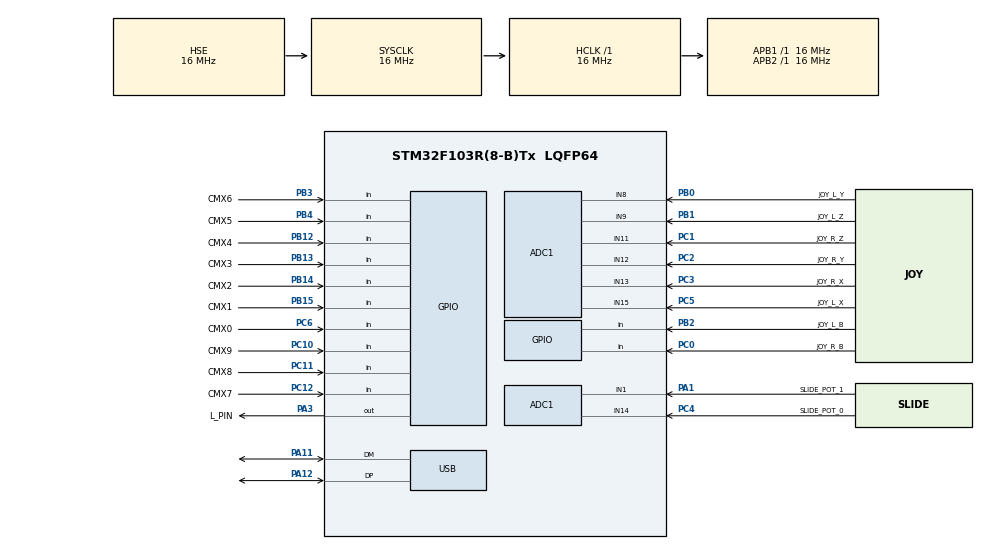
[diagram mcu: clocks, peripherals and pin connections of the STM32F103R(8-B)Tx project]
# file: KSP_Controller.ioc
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ADC1.Channel-0\#ChannelRegularConversion=ADC_CHANNEL_14
ADC1.Channel-1\#ChannelRegularConversion=ADC_CHANNEL_15
ADC1.Channel-2\#ChannelRegularConversion=ADC_CHANNEL_8
ADC1.Channel-3\#ChannelRegularConversion=ADC_CHANNEL_9
ADC1.Channel-4\#ChannelRegularConversion=ADC_CHANNEL_1
ADC1.Channel-5\#ChannelRegularConversion=ADC_CHANNEL_13
ADC1.Channel-6\#ChannelRegularConversion=ADC_CHANNEL_12
ADC1.Channel-7\#ChannelRegularConversion=ADC_CHANNEL_11
ADC1.ContinuousConvMode=DISABLE
ADC1.DiscontinuousConvMode=DISABLE
ADC1.NbrOfConversion=8
ADC1.NbrOfConversionFlag=1
ADC1.Rank-0\#ChannelRegularConversion=1
ADC1.Rank-1\#ChannelRegularConversion=2
ADC1.Rank-2\#ChannelRegularConversion=3
ADC1.Rank-3\#ChannelRegularConversion=4
ADC1.Rank-4\#ChannelRegularConversion=5
ADC1.Rank-5\#ChannelRegularConversion=6
ADC1.Rank-6\#ChannelRegularConversion=7
ADC1.Rank-7\#ChannelRegularConversion=8
ADC1.SamplingTime-0\#ChannelRegularConversion=ADC_SAMPLETIME_1CYCLE_5
ADC1.SamplingTime-1\#ChannelRegularConversion=ADC_SAMPLETIME_1CYCLE_5
ADC1.SamplingTime-2\#ChannelRegularConversion=ADC_SAMPLETIME_1CYCLE_5
ADC1.SamplingTime-3\#ChannelRegularConversion=ADC_SAMPLETIME_1CYCLE_5
ADC1.SamplingTime-4\#ChannelRegularConversion=ADC_SAMPLETIME_1CYCLE_5
ADC1.SamplingTime-5\#ChannelRegularConversion=ADC_SAMPLETIME_1CYCLE_5
ADC1.SamplingTime-6\#ChannelRegularConversion=ADC_SAMPLETIME_1CYCLE_5
ADC1.SamplingTime-7\#ChannelRegularConversion=ADC_SAMPLETIME_1CYCLE_5
ADC1.master=1
Dma.ADC1.0.Direction=DMA_PERIPH_TO_MEMORY
Dma.ADC1.0.Instance=DMA1_Channel1
Dma.ADC1.0.MemDataAlignment=DMA_MDATAALIGN_WORD
Dma.ADC1.0.MemInc=DMA_MINC_ENABLE
Dma.ADC1.0.Mode=DMA_CIRCULAR
Dma.ADC1.0.PeriphDataAlignment=DMA_PDATAALIGN_WORD
Dma.ADC1.0.PeriphInc=DMA_PINC_DISABLE
Dma.ADC1.0.Priority=DMA_PRIORITY_LOW
Dma.Request0=ADC1
Mcu.Family=STM32F1
Mcu.Name=STM32F103R(8-B)Tx
Mcu.Package=LQFP64
NVIC.DMA1_Channel1_IRQn=true\:0\:0\:false\:false\:true\:false\:true\:true
NVIC.PriorityGroup=NVIC_PRIORITYGROUP_4
NVIC.USB_LP_CAN1_RX0_IRQn=true\:0\:0\:false\:false\:true\:false\:true\:true
PA1.GPIO_Label=SLIDE_POT_1
PA1.Signal=ADCx_IN1
PA11.Mode=Device
PA11.Signal=USB_DM
PA12.Mode=Device
PA12.Signal=USB_DP
PA13.Mode=Serial_Wire
PA13.Signal=SYS_JTMS-SWDIO
PA14.Mode=Serial_Wire
PA14.Signal=SYS_JTCK-SWCLK
PA3.GPIO_Label=L_PIN
PA3.GPIO_PuPd=GPIO_PULLDOWN
PA3.Signal=GPIO_Output
PB0.GPIO_Label=JOY_L_Y
PB0.Signal=ADCx_IN8
PB1.GPIO_Label=JOY_L_Z
PB1.Signal=ADCx_IN9
PB12.GPIO_Label=CMX4
PB12.GPIO_PuPd=GPIO_PULLDOWN
PB12.Signal=GPIO_Input
PB13.GPIO_Label=CMX3
PB13.GPIO_PuPd=GPIO_PULLDOWN
PB13.Signal=GPIO_Input
PB14.GPIO_Label=CMX2
PB14.GPIO_PuPd=GPIO_PULLDOWN
PB14.Signal=GPIO_Input
PB15.GPIO_Label=CMX1
PB15.GPIO_PuPd=GPIO_PULLDOWN
PB15.Signal=GPIO_Input
PB2.GPIO_Label=JOY_L_B
PB2.GPIO_PuPd=GPIO_PULLDOWN
PB2.Signal=GPIO_Input
PB3.GPIO_Label=CMX6
PB3.GPIO_PuPd=GPIO_PULLDOWN
PB3.Signal=GPIO_Input
PB4.GPIO_Label=CMX5
PB4.GPIO_PuPd=GPIO_PULLDOWN
PB4.Signal=GPIO_Input
PC0.GPIO_Label=JOY_R_B
PC0.GPIO_PuPd=GPIO_PULLDOWN
PC0.Signal=GPIO_Input
PC1.GPIO_Label=JOY_R_Z
PC1.Signal=ADCx_IN11
PC10.GPIO_Label=CMX9
PC10.GPIO_PuPd=GPIO_PULLDOWN
PC10.Signal=GPIO_Input
PC11.GPIO_Label=CMX8
PC11.GPIO_PuPd=GPIO_PULLDOWN
PC11.Signal=GPIO_Input
PC12.GPIO_Label=CMX7
PC12.GPIO_PuPd=GPIO_PULLDOWN
PC12.Signal=GPIO_Input
PC2.GPIO_Label=JOY_R_Y
PC2.Signal=ADCx_IN12
PC3.GPIO_Label=JOY_R_X
PC3.Signal=ADCx_IN13
PC4.GPIO_Label=SLIDE_POT_0
PC4.Signal=ADCx_IN14
PC5.GPIO_Label=JOY_L_X
PC5.Signal=ADCx_IN15
PC6.GPIO_Label=CMX0
PC6.GPIO_PuPd=GPIO_PULLDOWN
PC6.Signal=GPIO_Input
PD0-OSC_IN.Mode=HSE-External-Oscillator
PD0-OSC_IN.Signal=RCC_OSC_IN
PD1-OSC_OUT.Mode=HSE-External-Oscillator
PD1-OSC_OUT.Signal=RCC_OSC_OUT
ProjectManager.HeapSize=0x1000
ProjectManager.StackSize=0x400
ProjectManager.TargetToolchain=STM32CubeIDE
RCC.AHBFreq_Value=16000000
RCC.APB1Freq_Value=16000000
RCC.APB1TimFreq_Value=16000000
RCC.APB2Freq_Value=16000000
RCC.APB2TimFreq_Value=16000000
RCC.HCLKFreq_Value=16000000
RCC.HSE_VALUE=16000000
RCC.PLLMUL=RCC_PLL_MUL3
RCC.SYSCLKFreq_VALUE=16000000
RCC.SYSCLKSource=RCC_SYSCLKSOURCE_HSE
RCC.USBFreq_Value=48000000
SH.ADCx_IN1.0=ADC1_IN1,IN1
SH.ADCx_IN11.0=ADC1_IN11,IN11
SH.ADCx_IN12.0=ADC1_IN12,IN12
SH.ADCx_IN13.0=ADC1_IN13,IN13
SH.ADCx_IN14.0=ADC1_IN14,IN14
SH.ADCx_IN15.0=ADC1_IN15,IN15
SH.ADCx_IN8.0=ADC1_IN8,IN8
SH.ADCx_IN9.0=ADC1_IN9,IN9
USB_DEVICE.CLASS_NAME_FS=CUSTOM_HID
USB_DEVICE.CUSTOM_HID_FS_BINTERVAL=1
USB_DEVICE.MANUFACTURER_STRING=JLS Hobbies
USB_DEVICE.PID_CUSTOMHID_FS=0x6789
USB_DEVICE.PRODUCT_STRING_CUSTOMHID_FS=KSP Controller
USB_DEVICE.USBD_CUSTOMHID_OUTREPORT_BUF_SIZE=8
USB_DEVICE.USBD_CUSTOM_HID_REPORT_DESC_SIZE=56
USB_DEVICE.USBD_DEBUG_LEVEL=3
USB_DEVICE.USBD_MAX_NUM_CONFIGURATION=1
USB_DEVICE.USBD_MAX_NUM_INTERFACES=1
USB_DEVICE.VID=0x5432
USB_DEVICE.VirtualMode=CustomHid
USB_DEVICE.VirtualModeFS=Custom_Hid_FS
VP_USB_DEVICE_VS_USB_DEVICE_CUSTOM_HID_FS.Mode=CUSTOM_HID_FS
board=custom

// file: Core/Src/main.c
/* USER CODE BEGIN Header */
/**
  ******************************************************************************
  * @file           : main.c
  * @brief          : Main program body
  ******************************************************************************
  * @attention
  *
  * Copyright (c) 2023 STMicroelectronics.
  * All rights reserved.
  *
  * This software is licensed under terms that can be found in the LICENSE file
  * in the root directory of this software component.
  * If no LICENSE file comes with this software, it is provided AS-IS.
  *
  ******************************************************************************
  */
/* USER CODE END Header */
#include "main.h"
#include "usb_device.h"

/* USER CODE BEGIN Includes */
#include "kspcontroller.h"
#include "usbd_customhid.h"
/* USER CODE END Includes */

ADC_HandleTypeDef hadc1;
DMA_HandleTypeDef hdma_adc1;

/* USER CODE BEGIN PV */
extern USBD_HandleTypeDef hUsbDeviceFS;
extern kspControllerHIDStruct kspController;
/* USER CODE END PV */

void SystemClock_Config(void);
static void MX_GPIO_Init(void);
static void MX_DMA_Init(void);
static void MX_ADC1_Init(void);

int main(void)
{

  /* MCU Configuration--------------------------------------------------------*/

  /* Reset of all peripherals, Initializes the Flash interface and the Systick. */
  HAL_Init();

  /* Configure the system clock */
  SystemClock_Config();

  /* Initialize all configured peripherals */
  MX_GPIO_Init();
  MX_DMA_Init();
  MX_USB_DEVICE_Init();
  MX_ADC1_Init();
  /* USER CODE BEGIN 2 */
  kspcontroller_init();
  kspcontroller_setToCentre();

  /* USER CODE END 2 */

  /* Infinite loop */
  while (1)
  {

    /* USER CODE BEGIN 3 */
	  kspcontroller_update();
//	  HAL_Delay(50);
	  USBD_CUSTOM_HID_SendReport(&hUsbDeviceFS, (uint8_t*)&kspController, sizeof(kspController));
//	  HAL_Delay(450);
  }
  /* USER CODE END 3 */
}

void SystemClock_Config(void)
{
  RCC_OscInitTypeDef RCC_OscInitStruct = {0};
  RCC_ClkInitTypeDef RCC_ClkInitStruct = {0};
  RCC_PeriphCLKInitTypeDef PeriphClkInit = {0};

  /** Initializes the RCC Oscillators according to the specified parameters
  * in the RCC_OscInitTypeDef structure.
  */
  RCC_OscInitStruct.OscillatorType = RCC_OSCILLATORTYPE_HSE;
  RCC_OscInitStruct.HSEState = RCC_HSE_ON;
  RCC_OscInitStruct.HSEPredivValue = RCC_HSE_PREDIV_DIV1;
  RCC_OscInitStruct.HSIState = RCC_HSI_ON;
  RCC_OscInitStruct.PLL.PLLState = RCC_PLL_ON;
  RCC_OscInitStruct.PLL.PLLSource = RCC_PLLSOURCE_HSE;
  RCC_OscInitStruct.PLL.PLLMUL = RCC_PLL_MUL3;
  if (HAL_RCC_OscConfig(&RCC_OscInitStruct) != HAL_OK)
  {
    Error_Handler();
  }

  /** Initializes the CPU, AHB and APB buses clocks
  */
  RCC_ClkInitStruct.ClockType = RCC_CLOCKTYPE_HCLK|RCC_CLOCKTYPE_SYSCLK
                              |RCC_CLOCKTYPE_PCLK1|RCC_CLOCKTYPE_PCLK2;
  RCC_ClkInitStruct.SYSCLKSource = RCC_SYSCLKSOURCE_HSE;
  RCC_ClkInitStruct.AHBCLKDivider = RCC_SYSCLK_DIV1;
  RCC_ClkInitStruct.APB1CLKDivider = RCC_HCLK_DIV1;
  RCC_ClkInitStruct.APB2CLKDivider = RCC_HCLK_DIV1;

  if (HAL_RCC_ClockConfig(&RCC_ClkInitStruct, FLASH_LATENCY_0) != HAL_OK)
  {
    Error_Handler();
  }
  PeriphClkInit.PeriphClockSelection = RCC_PERIPHCLK_ADC|RCC_PERIPHCLK_USB;
  PeriphClkInit.AdcClockSelection = RCC_ADCPCLK2_DIV2;
  PeriphClkInit.UsbClockSelection = RCC_USBCLKSOURCE_PLL;
  if (HAL_RCCEx_PeriphCLKConfig(&PeriphClkInit) != HAL_OK)
  {
    Error_Handler();
  }
}

static void MX_ADC1_Init(void)
{

  ADC_ChannelConfTypeDef sConfig = {0};

  /** Common config
  */
  hadc1.Instance = ADC1;
  hadc1.Init.ScanConvMode = ADC_SCAN_ENABLE;
  hadc1.Init.ContinuousConvMode = DISABLE;
  hadc1.Init.DiscontinuousConvMode = DISABLE;
  hadc1.Init.ExternalTrigConv = ADC_SOFTWARE_START;
  hadc1.Init.DataAlign = ADC_DATAALIGN_RIGHT;
  hadc1.Init.NbrOfConversion = 8;
  if (HAL_ADC_Init(&hadc1) != HAL_OK)
  {
    Error_Handler();
  }

  /** Configure Regular Channel
  */
  sConfig.Channel = ADC_CHANNEL_14;
  sConfig.Rank = ADC_REGULAR_RANK_1;
  sConfig.SamplingTime = ADC_SAMPLETIME_1CYCLE_5;
  if (HAL_ADC_ConfigChannel(&hadc1, &sConfig) != HAL_OK)
  {
    Error_Handler();
  }

  /** Configure Regular Channel
  */
  sConfig.Channel = ADC_CHANNEL_15;
  sConfig.Rank = ADC_REGULAR_RANK_2;
  if (HAL_ADC_ConfigChannel(&hadc1, &sConfig) != HAL_OK)
  {
    Error_Handler();
  }

  /** Configure Regular Channel
  */
  sConfig.Channel = ADC_CHANNEL_8;
  sConfig.Rank = ADC_REGULAR_RANK_3;
  if (HAL_ADC_ConfigChannel(&hadc1, &sConfig) != HAL_OK)
  {
    Error_Handler();
  }

  /** Configure Regular Channel
  */
  sConfig.Channel = ADC_CHANNEL_9;
  sConfig.Rank = ADC_REGULAR_RANK_4;
  if (HAL_ADC_ConfigChannel(&hadc1, &sConfig) != HAL_OK)
  {
    Error_Handler();
  }

  /** Configure Regular Channel
  */
  sConfig.Channel = ADC_CHANNEL_1;
  sConfig.Rank = ADC_REGULAR_RANK_5;
  if (HAL_ADC_ConfigChannel(&hadc1, &sConfig) != HAL_OK)
  {
    Error_Handler();
  }

  /** Configure Regular Channel
  */
  sConfig.Channel = ADC_CHANNEL_13;
  sConfig.Rank = ADC_REGULAR_RANK_6;
  if (HAL_ADC_ConfigChannel(&hadc1, &sConfig) != HAL_OK)
  {
    Error_Handler();
  }

  /** Configure Regular Channel
  */
  sConfig.Channel = ADC_CHANNEL_12;
  sConfig.Rank = ADC_REGULAR_RANK_7;
  if (HAL_ADC_ConfigChannel(&hadc1, &sConfig) != HAL_OK)
  {
    Error_Handler();
  }

  /** Configure Regular Channel
  */
  sConfig.Channel = ADC_CHANNEL_11;
  sConfig.Rank = ADC_REGULAR_RANK_8;
  if (HAL_ADC_ConfigChannel(&hadc1, &sConfig) != HAL_OK)
  {
    Error_Handler();
  }

}

static void MX_DMA_Init(void)
{

  /* DMA controller clock enable */
  __HAL_RCC_DMA1_CLK_ENABLE();

  /* DMA interrupt init */
  /* DMA1_Channel1_IRQn interrupt configuration */
  HAL_NVIC_SetPriority(DMA1_Channel1_IRQn, 0, 0);
  HAL_NVIC_EnableIRQ(DMA1_Channel1_IRQn);

}

static void MX_GPIO_Init(void)
{
  GPIO_InitTypeDef GPIO_InitStruct = {0};

  /* GPIO Ports Clock Enable */
  __HAL_RCC_GPIOD_CLK_ENABLE();
  __HAL_RCC_GPIOC_CLK_ENABLE();
  __HAL_RCC_GPIOA_CLK_ENABLE();
  __HAL_RCC_GPIOB_CLK_ENABLE();

  /*Configure GPIO pin Output Level */
  HAL_GPIO_WritePin(L_PIN_GPIO_Port, L_PIN_Pin, GPIO_PIN_RESET);

  /*Configure GPIO pins : JOY_R_B_Pin CMX0_Pin CMX9_Pin CMX8_Pin
                           CMX7_Pin */
  GPIO_InitStruct.Pin = JOY_R_B_Pin|CMX0_Pin|CMX9_Pin|CMX8_Pin
                          |CMX7_Pin;
  GPIO_InitStruct.Mode = GPIO_MODE_INPUT;
  GPIO_InitStruct.Pull = GPIO_PULLDOWN;
  HAL_GPIO_Init(GPIOC, &GPIO_InitStruct);

  /*Configure GPIO pin : L_PIN_Pin */
  GPIO_InitStruct.Pin = L_PIN_Pin;
  GPIO_InitStruct.Mode = GPIO_MODE_OUTPUT_PP;
  GPIO_InitStruct.Pull = GPIO_PULLDOWN;
  GPIO_InitStruct.Speed = GPIO_SPEED_FREQ_LOW;
  HAL_GPIO_Init(L_PIN_GPIO_Port, &GPIO_InitStruct);

  /*Configure GPIO pins : JOY_L_B_Pin CMX4_Pin CMX3_Pin CMX2_Pin
                           CMX1_Pin CMX6_Pin CMX5_Pin */
  GPIO_InitStruct.Pin = JOY_L_B_Pin|CMX4_Pin|CMX3_Pin|CMX2_Pin
                          |CMX1_Pin|CMX6_Pin|CMX5_Pin;
  GPIO_InitStruct.Mode = GPIO_MODE_INPUT;
  GPIO_InitStruct.Pull = GPIO_PULLDOWN;
  HAL_GPIO_Init(GPIOB, &GPIO_InitStruct);

}

void Error_Handler(void)
{
  __disable_irq();
  while (1)
  {
  }
}
